AUTOSAR XML (schema 4.0)
standard types defined: float32, float64, sint16, sint32, sint8, uint16, uint32, uint8, void, boolean
package /ImplDataTypes
  impl type BatteryLevel: implementation-data-type=uint16, type-emitter=RTE
package /MappingSets
  data type mapping set MappingSet
package /PortInterfaces/SenderReceiver
  sender receiver interface SrIf_BatteryInfo
    data BatteryLevel: type=BatteryLevel
package /SoftwareComponents
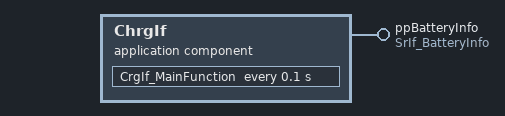
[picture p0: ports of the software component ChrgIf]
  application sw component type ChrgIf
    provide port ppBatteryInfo: provided-interface=SrIf_BatteryInfo
    behavior Ibhv_ChrgIf: data-type-mapping=MappingSet, handle-termination-and-restart=NO-SUPPORT
      timing event TE_CrgIf_MainFunction_100ms: start-on-event=CrgIf_MainFunction, period=0.1
      runnable CrgIf_MainFunction
        data-send-points:
          access DSP_ppBatteryInfo_BatteryLevel: accessed-variable=ppBatteryInfo.BatteryLevel
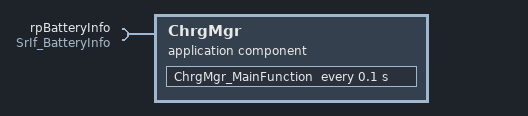
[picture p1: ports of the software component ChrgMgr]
  application sw component type ChrgMgr
    require port rpBatteryInfo: required-interface=SrIf_BatteryInfo
    behavior Ibhv_ChrgMgr: data-type-mapping=MappingSet, handle-termination-and-restart=NO-SUPPORT
      timing event TE_ChrgMgr_MainFunction_100ms: start-on-event=ChrgMgr_MainFunction, period=0.1
      runnable ChrgMgr_MainFunction
        data-receive-point-by-arguments:
          access DRP_rpBatteryInfo_BatteryLevel: accessed-variable=rpBatteryInfo.BatteryLevel
  swc implementation Impl_ChrgIf: programming-language=C, sw-version=1.0.0, vendor-id=255, behavior=Ibhv_ChrgIf
    code-descriptors:
      code Code: artifact-descriptors=autosar-engineering-object={short-label=SWC.c, category=SWSRC}
    resource consumption ResourceConsumption
  swc implementation Impl_ChrgMgr: programming-language=C, sw-version=1.0.0, vendor-id=255, behavior=Ibhv_ChrgMgr
    code-descriptors:
      code Code: artifact-descriptors=autosar-engineering-object={short-label=SWC.c, category=SWSRC}
    resource consumption ResourceConsumption
package /Compositions
  composition sw component type OBCSampleAppComposition
    component ChrgIf: type=ChrgIf
    component ChrgMgr: type=ChrgMgr
    connect ChrgIf.ppBatteryInfo -> ChrgMgr.rpBatteryInfo
